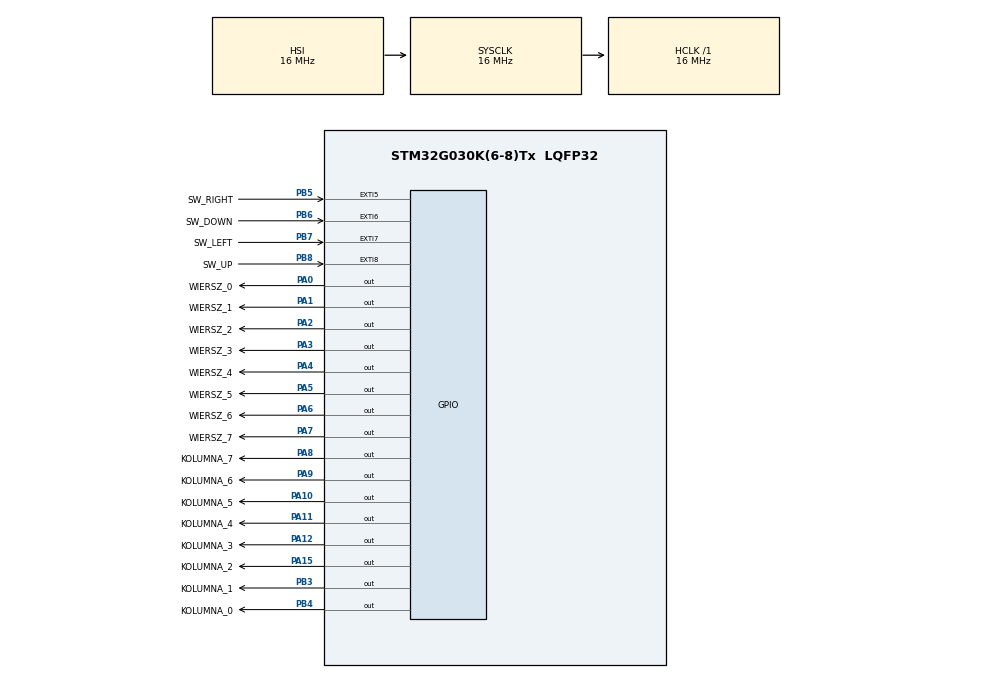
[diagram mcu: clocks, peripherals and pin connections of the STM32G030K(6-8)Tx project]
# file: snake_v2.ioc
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Mcu.Family=STM32G0
Mcu.Name=STM32G030K(6-8)Tx
Mcu.Package=LQFP32
NVIC.EXTI4_15_IRQn=true\:0\:0\:false\:false\:true\:true\:true
NVIC.TIM14_IRQn=true\:0\:0\:false\:false\:true\:true\:true
PA0.GPIO_Label=WIERSZ_0
PA0.Signal=GPIO_Output
PA1.GPIO_Label=WIERSZ_1
PA1.Signal=GPIO_Output
PA10.GPIO_Label=KOLUMNA_5
PA10.Signal=GPIO_Output
PA11\ [PA9].GPIO_Label=KOLUMNA_4
PA11\ [PA9].Signal=GPIO_Output
PA12\ [PA10].GPIO_Label=KOLUMNA_3
PA12\ [PA10].Signal=GPIO_Output
PA13.Mode=Serial_Wire
PA13.Signal=SYS_SWDIO
PA14-BOOT0.Mode=Serial_Wire
PA14-BOOT0.Signal=SYS_SWCLK
PA15.GPIO_Label=KOLUMNA_2
PA15.Signal=GPIO_Output
PA2.GPIO_Label=WIERSZ_2
PA2.Signal=GPIO_Output
PA3.GPIO_Label=WIERSZ_3
PA3.Signal=GPIO_Output
PA4.GPIO_Label=WIERSZ_4
PA4.Signal=GPIO_Output
PA5.GPIO_Label=WIERSZ_5
PA5.Signal=GPIO_Output
PA6.GPIO_Label=WIERSZ_6
PA6.Signal=GPIO_Output
PA7.GPIO_Label=WIERSZ_7
PA7.Signal=GPIO_Output
PA8.GPIO_Label=KOLUMNA_7
PA8.Signal=GPIO_Output
PA9.GPIO_Label=KOLUMNA_6
PA9.Signal=GPIO_Output
PB3.GPIO_Label=KOLUMNA_1
PB3.Signal=GPIO_Output
PB4.GPIO_Label=KOLUMNA_0
PB4.Signal=GPIO_Output
PB5.GPIO_Label=SW_RIGHT
PB5.GPIO_ModeDefaultEXTI=GPIO_MODE_IT_FALLING
PB5.GPIO_PuPd=GPIO_NOPULL
PB5.Signal=GPXTI5
PB6.GPIO_Label=SW_DOWN
PB6.GPIO_ModeDefaultEXTI=GPIO_MODE_IT_FALLING
PB6.GPIO_PuPd=GPIO_NOPULL
PB6.Signal=GPXTI6
PB7.GPIO_Label=SW_LEFT
PB7.GPIO_ModeDefaultEXTI=GPIO_MODE_IT_FALLING
PB7.GPIO_PuPd=GPIO_NOPULL
PB7.Signal=GPXTI7
PB8.GPIO_Label=SW_UP
PB8.GPIO_ModeDefaultEXTI=GPIO_MODE_IT_FALLING
PB8.GPIO_PuPd=GPIO_NOPULL
PB8.Signal=GPXTI8
ProjectManager.HeapSize=0x200
ProjectManager.StackSize=0x400
ProjectManager.TargetToolchain=STM32CubeIDE
RCC.AHBFreq_Value=16000000
RCC.CortexFreq_Value=16000000
RCC.EXTERNAL_CLOCK_VALUE=12288000
RCC.HCLKFreq_Value=16000000
RCC.HSE_VALUE=8000000
RCC.HSI_VALUE=16000000
RCC.LSE_VALUE=32768
RCC.SYSCLKFreq_VALUE=16000000
RCC.VCOOutputFreq_Value=128000000
TIM14.AutoReloadPreload=TIM_AUTORELOAD_PRELOAD_ENABLE
TIM14.Period=1
TIM14.Prescaler=499
VP_TIM14_VS_ClockSourceINT.Mode=Enable_Timer
board=custom

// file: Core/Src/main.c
/* USER CODE BEGIN Header */
/**
  ******************************************************************************
  * @file           : main.c
  * @brief          : Main program body
  ******************************************************************************
  * @attention
  *
  * <h2><center>&copy; Copyright (c) 2020 STMicroelectronics.
  * All rights reserved.</center></h2>
  *
  * This software component is licensed by ST under BSD 3-Clause license,
  * the "License"; You may not use this file except in compliance with the
  * License. You may obtain a copy of the License at:
  *                        opensource.org/licenses/BSD-3-Clause
  *
  ******************************************************************************
  */
/* USER CODE END Header */

#include "main.h"
#include "tim.h"
#include "gpio.h"

/* USER CODE BEGIN Includes */
#include "snake.h"
/* USER CODE END Includes */

/* USER CODE BEGIN PV */

uint16_t which_sw = 0x0100;

/* USER CODE END PV */

void SystemClock_Config(void);

int main(void)
{

  /* MCU Configuration--------------------------------------------------------*/

  /* Reset of all peripherals, Initializes the Flash interface and the Systick. */
  HAL_Init();

  /* Configure the system clock */
  SystemClock_Config();

  /* Initialize all configured peripherals */
  MX_GPIO_Init();
  MX_TIM14_Init();
  /* USER CODE BEGIN 2 */
  HAL_TIM_Base_Start_IT(&htim14);
  which_sw = UP;
//  char string[60] = "GAME OVER";
  /* USER CODE END 2 */

  /* Infinite loop */
  /* USER CODE BEGIN WHILE */
	while (1) {
//		print_scroll("SNAKE", 1, 75, SCROLL_LEFT);
//		char buff[2] = {which_sw};
//		print_center(buff);
		start_gameplay_snake();
//		print_scroll("WWW.EKO-LED.COM.PL", 1, 75, SCROLL_LEFT);

    /* USER CODE END WHILE */

	}
}

void SystemClock_Config(void)
{
  RCC_OscInitTypeDef RCC_OscInitStruct = {0};
  RCC_ClkInitTypeDef RCC_ClkInitStruct = {0};

  /** Configure the main internal regulator output voltage
  */
  HAL_PWREx_ControlVoltageScaling(PWR_REGULATOR_VOLTAGE_SCALE1);
  /** Initializes the CPU, AHB and APB busses clocks
  */
  RCC_OscInitStruct.OscillatorType = RCC_OSCILLATORTYPE_HSI;
  RCC_OscInitStruct.HSIState = RCC_HSI_ON;
  RCC_OscInitStruct.HSIDiv = RCC_HSI_DIV1;
  RCC_OscInitStruct.HSICalibrationValue = RCC_HSICALIBRATION_DEFAULT;
  RCC_OscInitStruct.PLL.PLLState = RCC_PLL_NONE;
  if (HAL_RCC_OscConfig(&RCC_OscInitStruct) != HAL_OK)
  {
    Error_Handler();
  }
  /** Initializes the CPU, AHB and APB busses clocks
  */
  RCC_ClkInitStruct.ClockType = RCC_CLOCKTYPE_HCLK|RCC_CLOCKTYPE_SYSCLK
                              |RCC_CLOCKTYPE_PCLK1;
  RCC_ClkInitStruct.SYSCLKSource = RCC_SYSCLKSOURCE_HSI;
  RCC_ClkInitStruct.AHBCLKDivider = RCC_SYSCLK_DIV1;
  RCC_ClkInitStruct.APB1CLKDivider = RCC_HCLK_DIV1;

  if (HAL_RCC_ClockConfig(&RCC_ClkInitStruct, FLASH_LATENCY_0) != HAL_OK)
  {
    Error_Handler();
  }
}

/* USER CODE BEGIN 4 */

void clear_screen() {
	HAL_GPIO_WritePin(GPIOA, 0x00FF, WIERSZ_OFF);
	HAL_GPIO_WritePin(GPIOA, 0xFF00, KOLUMNA_OFF);
	HAL_GPIO_WritePin(GPIOB, KOLUMNA_0_Pin | KOLUMNA_1_Pin, KOLUMNA_OFF);
}

/* USER CODE END 4 */

void Error_Handler(void)
{
}

/************************ (C) COPYRIGHT STMicroelectronics *****END OF FILE****/
